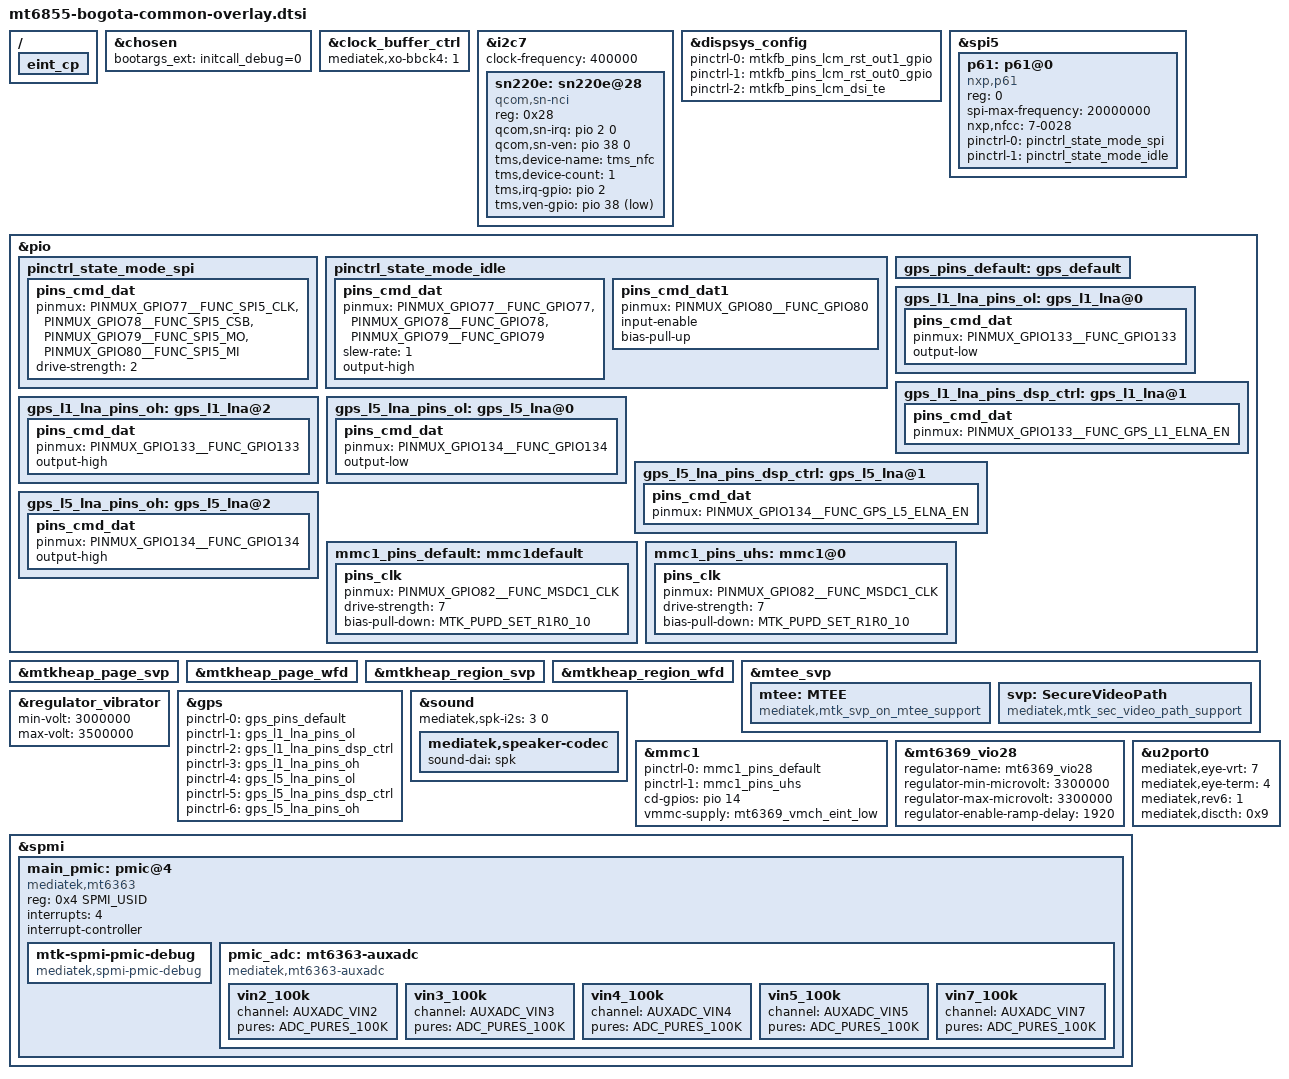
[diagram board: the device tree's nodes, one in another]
/* Copyright (c) 2020, The Linux Foundation. All rights reserved.
 *
 * This program is free software; you can redistribute it and/or modify
 * it under the terms of the GNU General Public License version 2 and
 * only version 2 as published by the Free Software Foundation.
 *
 * This program is distributed in the hope that it will be useful,
 * but WITHOUT ANY WARRANTY; without even the implied warranty of
 * MERCHANTABILITY or FITNESS FOR A PARTICULAR PURPOSE.  See the
 * GNU General Public License for more details.
 */

#include "mediatek/mt6855-moto-common-overlay.dtsi"
#include <dt-bindings/gpio/gpio.h>
#include "mediatek/bogota-display.dtsi"
#include "mediatek/bogota-touch.dtsi"
#include "mediatek/mt6855_bogota_camera_overlay.dtsi"
#include "mediatek/bogota-sar.dtsi"
#include "mediatek/bogota-audio.dtsi"
#include "mediatek/bogota-fps.dtsi"
#include "mediatek/mt6855-moto-memory-hdcp.dtsi"
#include "mediatek/bogota-fmr.dtsi"

#include <dt-bindings/iio/mt635x-auxadc.h>
#include <dt-bindings/spmi/spmi.h>

&chosen {
	bootargs_ext = "initcall_debug=0";
};

&clock_buffer_ctrl {
        mediatek,xo-bbck4 = <1>;
};
&i2c7 {
     clock-frequency = <400000>;

     sn220e: sn220e@28 {
                compatible = "qcom,sn-nci";
                reg = <0x28>;
                //NXP NFC
                qcom,sn-irq = <&pio 2 0>;
                qcom,sn-ven = <&pio 38 0>;
                status = "okay";
                // TMS NFC
                tms,device-name = "tms_nfc";
                tms,device-count = <1>;
                tms,irq-gpio = <&pio 2 0x00>;
                tms,ven-gpio = <&pio 38 0x01>;
     };
};

&dispsys_config {
	pinctrl-names =
		"lcm_rst_out1_gpio", "lcm_rst_out0_gpio",
		"mode_te_te";
	pinctrl-0 = <&mtkfb_pins_lcm_rst_out1_gpio>;
	pinctrl-1 = <&mtkfb_pins_lcm_rst_out0_gpio>;
	pinctrl-2 = <&mtkfb_pins_lcm_dsi_te>;
	status = "okay";
};

&spi5 {
	p61: p61@0 {
		compatible = "nxp,p61";
		reg = <0>;
		spi-max-frequency = <20000000>;
		nxp,nfcc = "7-0028";
//		nxp,p61-rst = <&gpio2 5 0>;
		pinctrl-names = "pinctrl_state_mode_spi",
				"pinctrl_state_mode_idle";
		pinctrl-0 = <&pinctrl_state_mode_spi>;
		pinctrl-1 = <&pinctrl_state_mode_idle>;
		status = "okay";
	};
};

&pio {
        pinctrl_state_mode_spi: pinctrl_state_mode_spi {
                pins_cmd_dat {
                        pinmux = <PINMUX_GPIO77__FUNC_SPI5_CLK>,
                                 <PINMUX_GPIO78__FUNC_SPI5_CSB>,
                                 <PINMUX_GPIO79__FUNC_SPI5_MO>,
                                 <PINMUX_GPIO80__FUNC_SPI5_MI>;
                        drive-strength = <2>;
                };
        };
        pinctrl_state_mode_idle: pinctrl_state_mode_idle {
                pins_cmd_dat {
                        pinmux = <PINMUX_GPIO77__FUNC_GPIO77>,<PINMUX_GPIO78__FUNC_GPIO78>,<PINMUX_GPIO79__FUNC_GPIO79>;
                        slew-rate = <1>;
                        output-high;
                };
                pins_cmd_dat1 {
			pinmux = <PINMUX_GPIO80__FUNC_GPIO80>;
			input-enable;
			bias-pull-up;
		};
        };
};


/* SVP */
&mtkheap_page_svp {
    status = "ok";
};

&mtkheap_page_wfd {
    status = "ok";
};

&mtkheap_region_svp {
    status = "ok";
};

&mtkheap_region_wfd {
    status = "ok";
};

&mtee_svp {
	mtee: MTEE {
		compatible = "mediatek,mtk_svp_on_mtee_support";
	};
	svp: SecureVideoPath {
		compatible = "mediatek,mtk_sec_video_path_support";
	};
};

&regulator_vibrator {
	min-volt = <3000000>;
	max-volt = <3500000>;
	status = "ok";
};

/* GPS GPIO standardization start */
&pio {
	gps_pins_default: gps_default {
	};
	gps_l1_lna_pins_ol: gps_l1_lna@0 {
		pins_cmd_dat {
			pinmux = <PINMUX_GPIO133__FUNC_GPIO133>;
			output-low;
		};
	};
	gps_l1_lna_pins_dsp_ctrl: gps_l1_lna@1 {
		pins_cmd_dat {
			pinmux = <PINMUX_GPIO133__FUNC_GPS_L1_ELNA_EN>;
		};
	};
	gps_l1_lna_pins_oh: gps_l1_lna@2 {
		pins_cmd_dat {
			pinmux = <PINMUX_GPIO133__FUNC_GPIO133>;
			output-high;
		};
	};
	gps_l5_lna_pins_ol: gps_l5_lna@0 {
		pins_cmd_dat {
			pinmux = <PINMUX_GPIO134__FUNC_GPIO134>;
			output-low;
		};
	};
	gps_l5_lna_pins_dsp_ctrl: gps_l5_lna@1 {
		pins_cmd_dat {
			pinmux = <PINMUX_GPIO134__FUNC_GPS_L5_ELNA_EN>;
		};
	};
	gps_l5_lna_pins_oh: gps_l5_lna@2 {
		pins_cmd_dat {
			pinmux = <PINMUX_GPIO134__FUNC_GPIO134>;
			output-high;
		};
	};
};



&gps {
	pinctrl-names = "default",
		"gps_l1_lna_disable",
		"gps_l1_lna_dsp_ctrl",
		"gps_l1_lna_enable",
		"gps_l5_lna_disable",
		"gps_l5_lna_dsp_ctrl",
		"gps_l5_lna_enable";
	pinctrl-0 = <&gps_pins_default>;
	pinctrl-1 = <&gps_l1_lna_pins_ol>;
	pinctrl-2 = <&gps_l1_lna_pins_dsp_ctrl>;
	pinctrl-3 = <&gps_l1_lna_pins_oh>;
	pinctrl-4 = <&gps_l5_lna_pins_ol>;
	pinctrl-5 = <&gps_l5_lna_pins_dsp_ctrl>;
	pinctrl-6 = <&gps_l5_lna_pins_oh>;
	status = "okay";
};
/* GPS GPIO standardization end */

#include "mediatek/cust_mt6855_camera_v4l2.dtsi"

/delete-node/ &camera_main_two_af_mtk;
/delete-node/ &camera_main_af_mtk;

&sound {
	mediatek,spk-i2s = <3 0>;
	mediatek,speaker-codec {
		sound-dai = <&spk>;
	};
};

&mmc1 {
	pinctrl-0 = <&mmc1_pins_default>;
	pinctrl-1 = <&mmc1_pins_uhs>;
	cd-gpios = <&pio 14 GPIO_ACTIVE_HIGH>;
	vmmc-supply = <&mt6369_vmch_eint_low>;
};

&pio {

        mmc1_pins_default: mmc1default {
		pins_clk {
			pinmux = <PINMUX_GPIO82__FUNC_MSDC1_CLK>;
			drive-strength = <7>;
			bias-pull-down = <MTK_PUPD_SET_R1R0_10>;
		};
	};
	mmc1_pins_uhs: mmc1@0{
		pins_clk {
			pinmux = <PINMUX_GPIO82__FUNC_MSDC1_CLK>;
			drive-strength = <7>;
			bias-pull-down = <MTK_PUPD_SET_R1R0_10>;
		};
	};
};

//for alsps sensor tmd2755x
&mt6369_vio28 {
	regulator-name = "mt6369_vio28";
	regulator-min-microvolt = <3300000>;
	regulator-max-microvolt = <3300000>;
	regulator-enable-ramp-delay = <1920>;
};

&u2port0{
	mediatek,eye-vrt = <7>;
	mediatek,eye-term = <4>;
	mediatek,rev6 = <1>;
	mediatek,discth = <0x9>;
};


//#include <k6855v1_64/cust.dtsi>
/*End of this file, DO NOT ADD ANYTHING HERE*/
&spmi {
	main_pmic: pmic@4 {
		compatible = "mediatek,mt6363";
		reg = <0x4 SPMI_USID>;
		interrupts = <4>;
		#address-cells = <1>;
		#size-cells = <0>;
		interrupt-controller;
		#interrupt-cells = <2>;

		mtk-spmi-pmic-debug {
			compatible = "mediatek,spmi-pmic-debug";
		};

		pmic_adc: mt6363-auxadc {
			compatible = "mediatek,mt6363-auxadc";
			#io-channel-cells = <1>;
			vin2_100k {
				channel = <AUXADC_VIN2>;
				pures = <ADC_PURES_100K>;
			};
			vin3_100k {
				channel = <AUXADC_VIN3>;
				pures = <ADC_PURES_100K>;
			};
			vin4_100k {
				channel = <AUXADC_VIN4>;
				pures = <ADC_PURES_100K>;
			};
			vin5_100k {
				channel = <AUXADC_VIN5>;
				pures = <ADC_PURES_100K>;
			};
			vin7_100k {
				channel = <AUXADC_VIN7>;
				pures = <ADC_PURES_100K>;
			};
		};

	};
};

/*charger pump eint int*/
/ {
eint_cp: eint_cp {
        };
};

#include "mediatek/bogota-ntc.dtsi"

